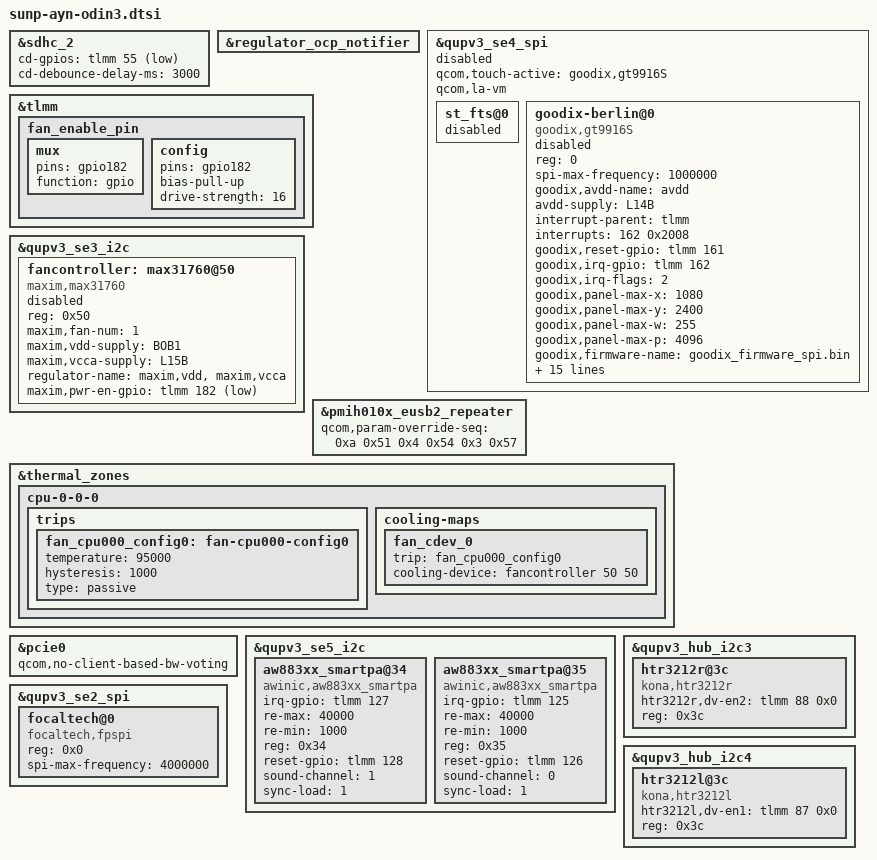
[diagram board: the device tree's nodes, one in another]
#include "../qcom/sun-qrd-sku1-v8.dtsi"
#include <dt-bindings/leds/common.h>

&sdhc_2 {
	cd-gpios = <&tlmm 55 GPIO_ACTIVE_LOW>;
	cd-debounce-delay-ms = <3000>;
};

&regulator_ocp_notifier {
	/delete-property/ periph-99b-supply;
	/delete-property/ periph-99e-supply;
	/delete-property/ periph-9a1-supply;
	/delete-property/ periph-9c1-supply;
	/delete-property/ periph-9c2-supply;
	/delete-property/ periph-9c3-supply;
	/delete-property/ periph-ac1-supply;
	/delete-property/ periph-ac2-supply;
	/delete-property/ periph-ac3-supply;
	/delete-property/ periph-ac4-supply;
	/delete-property/ periph-ac5-supply;
	/delete-property/ periph-ac6-supply;
	/delete-property/ periph-ac7-supply;
	/delete-property/ periph-c40-supply;
	/delete-property/ periph-c41-supply;
	/delete-property/ periph-c42-supply;
	/delete-property/ periph-c43-supply;
	/delete-property/ periph-c44-supply;
	/delete-property/ periph-c45-supply;
	/delete-property/ periph-c46-supply;
	/delete-property/ periph-d40-supply;
	/delete-property/ periph-d41-supply;
	/delete-property/ periph-d42-supply;
	/delete-property/ periph-d43-supply;
	/delete-property/ periph-d44-supply;
	/delete-property/ periph-d45-supply;
	/delete-property/ periph-d46-supply;
};

&qupv3_se4_spi {
	#address-cells = <1>;
	#size-cells = <0>;
	status = "disabled";
	qcom,touch-active = "goodix,gt9916S";
	qcom,la-vm;

	st_fts@0 {
		status = "disabled";
	};

	goodix-berlin@0 {
		compatible = "goodix,gt9916S";
		reg = <0>;
		spi-max-frequency = <1000000>;

		goodix,avdd-name = "avdd";
		avdd-supply = <&L14B>;

		interrupt-parent = <&tlmm>;
		interrupts = <162 0x2008>;
		goodix,reset-gpio = <&tlmm 161 0x00>;
		goodix,irq-gpio = <&tlmm 162 0x2008>;
		goodix,irq-flags = <2>;
		goodix,panel-max-x = <1080>;
		goodix,panel-max-y = <2400>;
		goodix,panel-max-w = <255>;
		goodix,panel-max-p = <4096>;
		goodix,firmware-name = "goodix_firmware_spi.bin";
		goodix,config-name = "goodix_cfg_group_spi.bin";

		pinctrl-names = "pmx_ts_active", "pmx_ts_suspend", "pmx_ts_release";
		pinctrl-0 = <&ts_active>;
		pinctrl-1 = <&ts_int_suspend &ts_reset_suspend>;
		pinctrl-2 = <&ts_release>;

		goodix,touch-type = "primary";
		goodix,qts_en;
		qts,trusted-touch-mode = "vm_mode";
		qts,touch-environment = "pvm";
		qts,trusted-touch-type = "primary";
		qts,trusted-touch-spi-irq = <652>;
		qts,trusted-touch-io-bases = <0xa90000>;
		qts,trusted-touch-io-sizes = <0x1000>;
		qts,trusted-touch-vm-gpio-list = <&tlmm 48 0 &tlmm 49 0 &tlmm 50 0
						&tlmm 51 0 &tlmm 161 0 &tlmm 162 0x2008>;
		status = "disabled";
	};
};

&tlmm {
	fan_enable_pin {
		mux {
			pins = "gpio182";
			function = "gpio";
		};

		config {
			pins = "gpio182";
			bias-pull-up;
			drive-strength = <16>;
		};
	};
};

&qupv3_se3_i2c {
	status = "ok";
	#address-cells = <1>;
	#size-cells = <0>;

	fancontroller: max31760@50 {
		compatible = "maxim,max31760";
		reg = <0x50>;
		#cooling-cells = <2>;
		maxim,fan-num = <1>;
		maxim,vdd-supply = <&BOB1>;
		maxim,vcca-supply = <&L15B>;
		regulator-name = "maxim,vdd", "maxim,vcca";
		maxim,pwr-en-gpio = <&tlmm 182 GPIO_ACTIVE_LOW>;
		status = "disabled";
	};
};

&pmih010x_eusb2_repeater {
	qcom,param-override-seq =
		/* <value reg_offset> */
		/* Adjust HS trasmit amplitude */
		<0xa 0x51
		/* Squelch detection threshold */
		 0x4 0x54
		/* Tx pre-emphasis tuning */
		 0x3 0x57>;
};

&thermal_zones {
	cpu-0-0-0 {
		trips {
			fan_cpu000_config0: fan-cpu000-config0 {
				temperature = <95000>;
				hysteresis = <1000>;
				type = "passive";
			};
		};

		cooling-maps {
			fan_cdev_0 {
				trip = <&fan_cpu000_config0>;
				cooling-device = <&fancontroller 50 50>;
			};
		};
	};
};

&pcie0 {
	qcom,no-client-based-bw-voting;
};

&qupv3_se5_i2c {
	status = "ok";

	aw883xx_smartpa@34 {
		compatible = "awinic,aw883xx_smartpa";
		irq-gpio = <&tlmm 127 0x0>;
		re-max = <40000>;
		re-min = <1000>;
		reg = <0x34>;
		reset-gpio = <&tlmm 128 0x0>;
		sound-channel = <1>;
		status = "okay";
		sync-load = <1>;
	};

	aw883xx_smartpa@35 {
		compatible = "awinic,aw883xx_smartpa";
		irq-gpio = <&tlmm 125 0x0>;
		re-max = <40000>;
		re-min = <1000>;
		reg = <0x35>;
		reset-gpio = <&tlmm 126 0x0>;
		sound-channel = <0>;
		status = "okay";
		sync-load = <1>;
	};
};

&qupv3_hub_i2c3 {
	#address-cells = <0x1>;
	#size-cells = <0x0>;
	status = "ok";

	htr3212r@3c {
		compatible = "kona,htr3212r";
		htr3212r,dv-en2 = <&tlmm 88 0x0>;
		reg = <0x3c>;
		status = "ok";
	};
};

&qupv3_hub_i2c4 {
	#address-cells = <0x1>;
	#size-cells = <0x0>;
	status = "ok";

	htr3212l@3c {
		compatible = "kona,htr3212l";
		htr3212l,dv-en1 = <&tlmm 87 0x0>;
		reg = <0x3c>;
		status = "ok";
	};
};

&qupv3_se2_spi {
	status = "ok";

	focaltech@0 {
		compatible = "focaltech,fpspi";
		reg = <0x0>;
		spi-max-frequency = <4000000>;
		status = "ok";
	};
};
